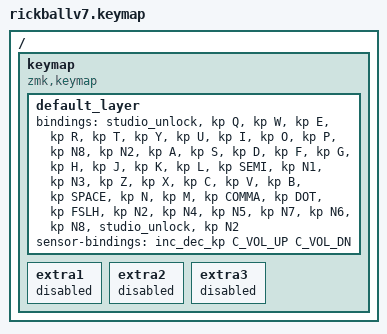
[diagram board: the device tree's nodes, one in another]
#include <behaviors.dtsi>
#include <dt-bindings/zmk/keys.h>

/ {
    keymap {
        compatible = "zmk,keymap";

        default_layer {
            bindings = <&studio_unlock &kp Q &kp W &kp E &kp R &kp T &kp Y &kp U &kp I &kp O &kp P &kp N8 &kp N2 &kp A &kp S &kp D &kp F &kp G &kp H &kp J &kp K &kp L &kp SEMI &kp N1 &kp N3 &kp Z &kp X &kp C &kp V &kp B &kp SPACE &kp N &kp M &kp COMMA &kp DOT &kp FSLH &kp N2 &kp N4 &kp N5 &kp N7 &kp N6 &kp N8 &studio_unlock &kp N2>;
            sensor-bindings = <&inc_dec_kp C_VOL_UP C_VOL_DN>;
        };

        extra1 {
            status = "reserved";
        };

        extra2 {
            status = "reserved";
        };

        extra3 {
            status = "reserved";
        };
    };
};
